# TC37XPD register map
Vendor: Infineon; Series: ATVMC; File version: 100
CPU: other r0p0, little endian, MPU, FPU, vendor SysTick, 4 interrupt priority bits
Registers are 32-bit, read-write, reset 0x0 unless marked. A register's access mark holds for its fields unless they carry their own. Offsets are from the block's base; [hi:lo] are bit positions; lines under a group give offsets from that group; {n}, {i} and the like mark numbered series; 'fields as' and 'values as' point back to an identical list.

## MINIMCDS
Base 0xFB718000
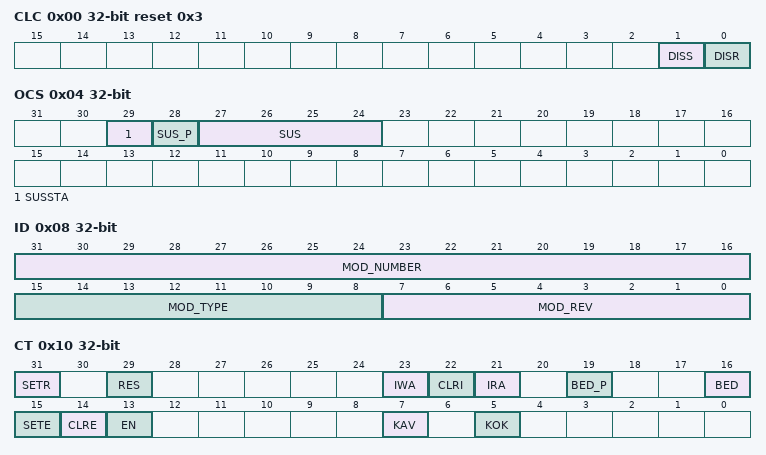
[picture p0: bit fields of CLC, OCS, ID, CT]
0x00 CLC access per field reset 0x3 — Clock Control Register resetvalue={PowerOn Reset:0x3}
  [1] DISS ro — Disable Status Bit DISS. This bit field indicates the current clocking state.
  [0] DISR rw — Disable Request Bit DISR. This bit is used to request a change of the clocking state. Turn off requests are ignored while the Flush flag is not asserted.
0x04 OCS access per field — OCDS Control and Status resetvalue={MCDS Reset:0x0}
  [29] SUSSTA ro — Suspend State inverted busy o SUSSTA
  [28] SUS_P wo — SUS Write Protection SUS P. SUS is only written when SUS P is 1 otherwise unchanged. Read as 0.
  [27:24] SUS rw — OCDS Suspend Control SUS. Controls the sensitivity to the suspend signal coming from the SCU before Power On Reset
0x08 ID ro reset not defined — Module Identification Register resetvalue={PowerOn Reset:0x0D6C007,MCDS Reset:0x0,Debug Reset:0x0}
  [31:16] MOD_NUMBER — Module Number MOD NUMBER
  [15:8] MOD_TYPE — Module Type MOD TYPE
  [7:0] MOD_REV — Module Revision MOD REV. This bit field indicates the revision number of the module implementation.
0x10 CT access per field reset not defined — MCDS Control Register resetvalue={PowerOn Reset:0x0A0,MCDS Reset:0x0,Debug Reset:0x0}
  [31] SETR wo — MCDS ResetRequest Bit SETR. This bit can be used to cause a MCDS Reset affecting debug resources like the MCDS registers as specified in the Reset behavior tables.
  [29] RES ro — MCDS ResetFlag RES. This bit reflects the current value of the MCDS Reset request. Granting of the request will automatically clear this bit.
  [23] IWA ro — Invalid Write Access Flag IWA. This bit field indicates whether any write access to the MCDS address range failed. The MCDS module ignores the data of erroneous writes.
  [22] CLRI wo — Clear Invalid Access Bits CLRI. This control bit is the only way the clear the error bits.
  [21] IRA ro — Invalid Read Access Flag IRA. This bit field indicates whether any read access to the MCDS address range failed. This is not a bus error the MCDS module just returns all zeros in this case.
  [19] BED_P wo — Bus Error Disable Protection BED P. This bit determines whether BED is changed by a write to the CT register.
  [16] BED rw — Bus Error Disable Flag BED. This bit field indicates whether writing to an SFR not implemented in the MCDS address space is considered an error. In TC3xx the usage of this bit is obsolete for miniMCDS.
  [15] SETE wo — Set MCDS Enable Flag SETE. This control bit is the only way to set the MCDS enable flag.
  [14] CLRE wo — Clear MCDS Enable Flag CLRE. This bit allows to reset the MCDS enable Flag by software and thus to write protect the MCDS address range.
  [13] EN ro — MCDS Enable Flag EN. This bit field indicates whether the MCDS is write enabled.
  [7] KAV ro — Key Available Flag KAV. This bit is always set for MINIMCDS .
  [5] KOK ro — Key OK Flag KOK. This bit is always set for MINIMCDS .
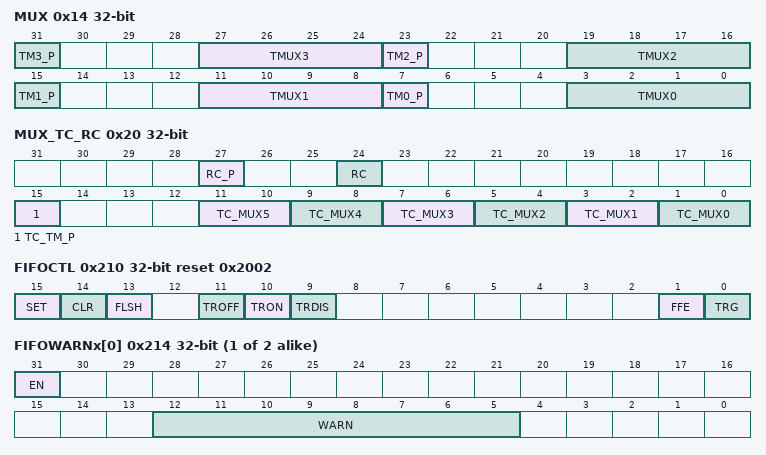
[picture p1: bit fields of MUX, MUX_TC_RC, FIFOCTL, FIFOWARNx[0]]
0x14 MUX access per field — MCDS Signal Source Control resetvalue={PowerOn Reset:0x0}
  [8n+7] TM{n}_P wo (n=0..3) — Trace Source Select 3 Protection TM3 P. This bit determines whether TMUXz is changed by a write to the MUX register. TM1 P TM2 P TM3 P are not relevant for miniMCDS.
  [27:24] TMUX3 rw — Trace Source Select 3 TMUX3. Not relevant for miniMCDS.
  [19:16] TMUX2 rw — Trace Source Select 2 TMUX2. Not relevant for miniMCDS.
  [11:8] TMUX1 rw — Trace Source Select 1 TMUX1. Not relevant for miniMCDS.
  [3:0] TMUX0 rw — Trace Source Select 0 TMUX0. This bit field determines which trace source is seen by POBx. This bit field can only be changed if TM0 P is written x2018 1 x2019 xa0 simultaneously. Not all sources are available in all products of the family. Please refer to Platform Feature Overview table of the TC3xx documentation.
0x20 MUX_TC_RC access per field — MCDS TC Signal Source Control resetvalue={PowerOn Reset:0x0}
  [27] RC_P wo — Reference Clock Select Protection RC P. This bit determines whether RC is changed by a write to the MUX TC RC register.
  [24] RC rw — Reference Clock Select RC. This control bit determines which source is used as reference clock by the TSU. This bit can only be changed if RC P is written 8216 1 8217 160 simultaneously. The reference clock source is sampled with the emulation clock. Therefore no reference clock faster than half the emulation clock must be used.
  [15] TC_TM_P wo — TC MUX Trace Source Select Protection TC TM P. This bit determines whether TC MUXz is changed by a write to the MUX TC RC register.
  [2n+1:2n] TC_MUX{n} rw (n=0..5) — TC MUX Trace Source Select TC MUX5. This bit field determines which trace source is selected. This bit field can only be changed if TC TM P is written 8216 1 8217 160 simultaneously. Not all CPUs are available in all products of the family.
0x200 FIFONOW ro — Trace Buffer Write Pointer resetvalue={PowerOn Reset:0x0}
  [12:5] NOW — Trace Buffer Current Write Pointer NOW. This number is the current value of the DMC s internal write pointer. When tracing stops this register points to the buffer memory word containing the lt end of trace gt message. The relevant width of the field depends on the size of the buffer memory see CROSSREFERENCE
0x204 FIFOBOT — Trace Buffer Bottom Register resetvalue={MCDS Reset:0x0}
  [12:10] BOTTOM — Trace Buffer lower Bound BOTTOM. See CROSSREFERENCE for a functional description. The relevant width of the field depends on the size of the buffer memory see CROSSREFERENCE
0x208 FIFOPRE — Trace Buffer PRE POST Register resetvalue={MCDS Reset:0x0}
  [12:5] PRE — Trace Buffer Pre Trigger Area Size PRE. See CROSSREFERENCE for a functional description. The relevant width of the field depends on the size of the buffer memory see CROSSREFERENCE
0x20C FIFOTOP reset 0x1FFF — Trace Buffer Top Register resetvalue={MCDS Reset:0x1FFF}
  [12:5] TOP — Trace Buffer upper Bound TOP. See CROSSREFERENCE for a functional description. The relevant width of the field depends on the size of the buffer memory see CROSSREFERENCE
0x210 FIFOCTL access per field reset 0x2002 — Trace Buffer Control Register resetvalue={PowerOn Reset:0x2002}
  [15] SET wo — SetFlushFlag SET. This write only bit is the only way to set the Flush flag by software.
  [14] CLR wo — ClearFlushFlag CLR. This write only bit is the only way to start trace recording.
  [13] FLSH ro — FlushFlag FLSH. This bit shows the current state of the Flush control signal. The Flush signal can be set by the SET bit and by the hardware at end of trace . The Flush signal can only be cleared by the CLR bit. This bit is automatically set by MCDS Reset .
  [11] TROFF wo — SetTrigger DisableFlag TROFF. This write only bit is the only way to set the Trigger Disable flag. It is used to mask disable all trigger pools of all TQUs.
  [10] TRON wo — ClearTrigger DisableFlag TRON. This write only bit is used by the tool to globally enable all trigger pools of all TQUs.
  [9] TRDIS ro — Trigger DisableFlag TRDIS. This bit shows the current state of the Trigger Disable control signal. The Trigger Disable signal can be set by the TROFF bit. The Trigger Disable signal can be cleared by the TRON bit. This bit is automatically reset by MCDS Reset .
  [1] FFE ro — FIFO Feeder Empty FFE. This bit indicates that all primary secondary and DMC internal FIFOs have been emptied. After Power On Reset and MCDS Reset this bit will be set automatically as the FIFOs are flushed synchronously.
  [0] TRG ro — Trigger Received Flag TRG. This bit indicated whether the trace recording is in the PRE or POST Trigger area. The switch is controlled by the trace done action of TQU MCX. The TRG flag is cleared by the next CLR bit.
{0x214+4i} FIFOWARNx[{i}] (i=0..1) — Trace Buffer Comparator Register resetvalue={MCDS Reset:0x0}
  [31] EN — Enable Trigger Generation EN
  [12:5] WARN — Trace Buffer Warn Level WARN. See CROSSREFERENCE for a functional description. The relevant width of the field depends on the size of the buffer memory see CROSSREFERENCE
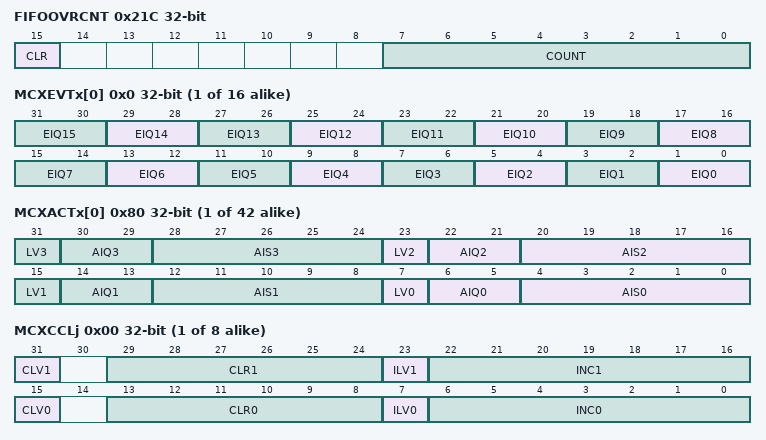
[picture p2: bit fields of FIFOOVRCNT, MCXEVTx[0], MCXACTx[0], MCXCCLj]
0x21C FIFOOVRCNT access per field — FIFO Overflow Counter Register resetvalue={PowerOn Reset:0x0}
  [15] CLR wo — Clear counter CLR
  [7:0] COUNT ro — FIFO Overflow Counter COUNT. The counter increments in case an ERR message is written to one of the Trace Unit FIFOs. In case multiple error messages are written the counter still increments just by one.
0x400 TSUREFCNT ro — Clock Counter Register resetvalue={PowerOn Reset:0x0}
  [31:0] COUNT — Current Count Value COUNT. For a functional description of the counter see CROSSREFERENCE .
0x404 TSUPRSCL — Clock Prescaler Register resetvalue={PowerOn Reset:0x0}
  [31:0] RELOAD — Prescaler Reload Value RELOAD. For a functional description of the prescaler see CROSSREFERENCE .
0x408 TSUEMUCNT ro — Clock Counter Register resetvalue={PowerOn Reset:0x0}
  fields as TSUREFCNT
0x800 MCX group
  {0x0+4j} MCXEVTx[{j}] (j=0..15) — Event Definition Register 0 resetvalue={MCDS Reset:0x0}
    [2n+1:2n] EIQ{n} (n=0..15) — Event Input Qualifier EIQ15. The value in this field determines how the trigger input named in the row of CROSSREFERENCE with value x in the column corresponding to this event definition is connected to the AND gate.
  {0x80+4j} MCXACTx[{j}] (j=0..41) — Action Definition Register 0 resetvalue={MCDS Reset:0x0}
    [8n+7] LV{n} (n=0..3) — Action Input Level Mode LV3. This bit determines how the event selected by AISq and processed according to AIQq is evaluated. The action is active for one emulation clock cycle if LVq is programmed 0.
    [8n+6:8n+5] AIQ{n} (n=0..3) — Action Input Qualifier AIQ3. The value in this field determines how the input bit x is connected to the OR gate edge detection.
    [8n+4:8n] AIS{n} (n=0..3) — Action Input Selector AIS3. Index of the event to be processed. Encoding see CROSSREFERENCE .
  {0x200+0x10*j} CNT[{j}] (j=0..7) group
    0x00 MCXCCLj — Counter Control Register resetvalue={MCDS Reset:0x0}
      [31] CLV1 — Clear Input Level Mode CLV1. For a functional description of the counter see CROSSREFERENCE .
      [29:24] CLR1 — Clear Input Selector CLR1. Index of the event to be processed. Encoding see CROSSREFERENCE . Note that the value 0 in this field does select nothing.
      [23] ILV1 — Count Input Level Mode ILV1. For a functional description of the counter see CROSSREFERENCE .
      [22:16] INC1 — Count Input Selector INC1. Index of the event to be processed. Encoding see CROSSREFERENCE . Note that the value 0 in this field does select nothing.
      [15] CLV0 — Clear Input Level Mode CLV1. For a functional description of the counter see CROSSREFERENCE .
      [13:8] CLR0 — Clear Input Selector CLR1. Index of the event to be processed. Encoding see CROSSREFERENCE . Note that the value 0 in this field does select nothing.
      [7] ILV0 — Count Input Level Mode ILV1. For a functional description of the counter see CROSSREFERENCE .
      [6:0] INC0 — Count Input Selector INC1. Index of the event to be processed. Encoding see CROSSREFERENCE . Note that the value 0 in this field does select nothing.
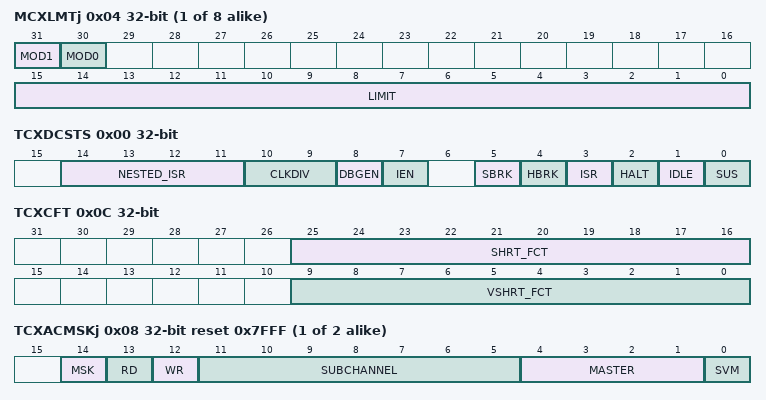
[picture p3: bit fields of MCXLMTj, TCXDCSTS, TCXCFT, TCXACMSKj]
    0x04 MCXLMTj — Counter Limit Register resetvalue={MCDS Reset:0x0}
      [31] MOD1 — Modulo Count Control MOD1. For a functional description of the counter see CROSSREFERENCE .
      [30] MOD0 — Modulo Count Control MOD1. For a functional description of the counter see CROSSREFERENCE .
      [15:0] LIMIT — Counter Limit LIMIT. For a functional description of the counter see CROSSREFERENCE .
    0x08 MCXCNTj ro — Current Count Register resetvalue={PowerOn Reset:0x0}
      [15:0] COUNT — Current Counter COUNT. For a functional description of the counter see CROSSREFERENCE .
0x2000 TCX group
  0x00 TCXDCSTS ro — Debug Status Register resetvalue={PowerOn Reset:0x0}
    [14:11] NESTED_ISR — Nested Interrupt Level NESTED ISR. The nested interrupt level is exactly indicated for nesting levels 0 15. For nesting levels greater 15 the value shown is 0xF.
    [10:9] CLKDIV — Current Clock Divider CLKDIV. The SCU provides the clock for the TriCore as well as for MCDS. The current ration is reported here.
    [8] DBGEN — Debug Enabled Flag DBGEN
    [7] IEN — Interrupt Enable Flag IEN
    [5] SBRK — Software Break Flag SBRK. This bit reflects the reaction to a DEBUG instruction filtered by the SWEVT register.
    [4] HBRK — Hardware Break Flag HBRK. This bit reflects the reaction to a break request from a OTGS trigger line filtered by the EXEVT register.
    [3] ISR — Interrupt Service Flag ISR. This bit indicated whether regular code or a trap interrupt handler is executed.
    [2] HALT — Halted Flag HALT. This is basically the DBGSR.HALT bit.
    [1] IDLE — Run Flag IDLE
    [0] SUS — Suspended Flag SUS
  0x08 TCXCIP ro — Current Instruction Pointer resetvalue={PowerOn Reset:0x0}
    [31:1] CURRENT — Current Instruction Pointer CURRENT. To help debugging the last valid value is kept when the TriCore stops executing. The value 0000 0000 indicates that no valid IP was ever seen.
  0x0C TCXCFT — Compact Function Trace Register resetvalue={MCDS Reset:0x0}
    [25:16] SHRT_FCT — Length of short leaf function SHRT FCT. This value has to be greater than VSHRT FCT if VSHRT FCT lt gt 0.
    [9:0] VSHRT_FCT — Length of very short leaf function VSHRT FCT. A TriCore 16 bit instruction corresponds to a value of 1 a 32 bit instruction to a value of 2.
  {0x400+0x10*j} EA[{j}] (j=0..1) group
    0x00 TCXEABNDj — Comparator Bound Register 0 resetvalue={MCDS Reset:0x0}
      [31:0] BOUND — Address Comparator range lower bound BOUND. For a functional description of the comparator see CROSSREFERENCE . When defining the comparators for the effective address keep in mind that many memory locations can be accessed under two different addresses namely as cached or non cached memory range.
    0x04 TCXEARNGj reset 0xFFFFFFFF — Comparator Range Register 0 resetvalue={MCDS Reset:0x0FFFFFFFF}
      [31:0] RANGE — Address Comparator range size RANGE. For a functional description of the comparator see CROSSREFERENCE .
  {0x480+0x20*j} WD[{j}] (j=0..1) group
    0x00 TCXWDBNDj — Comparator Bound Register 0 resetvalue={MCDS Reset:0x0}
      [31:0] BOUND — Data Comparator range lower bound BOUND. For a functional description of the comparator see CROSSREFERENCE .
    0x08 TCXWDRNGj — Comparator Range Register 0 resetvalue={MCDS Reset:0x0}
      [31:0] RANGE — Data Comparator range size RANGE. For a functional description of the comparator see CROSSREFERENCE .
    0x10 TCXWDMSKj reset 0xFFFFFFFF — Comparator Mask Register 0 resetvalue={MCDS Reset:0x0FFFFFFFF}
      [31:0] MASK — Data Comparator bit mask MASK. For a functional description of the comparator see CROSSREFERENCE .
    0x1C TCXWDSGNj — Comparator Sign Register 0 resetvalue={MCDS Reset:0x0}
      [4:0] SIGN — Bit number 1 31 of sign bit SIGN. For a functional description of the comparator see CROSSREFERENCE .
  {0x500+0x18*j} AC[{j}] (j=0..1) group
    0x00 TCXACBNDj — Comparator Bound Register 0 resetvalue={MCDS Reset:0x0}
      [13:0] BOUND — Mode Comparator range lower bound BOUND. The bit string consisting of SVM bus master ID sub channel and direction masked by TCXACMSKx is compared to this lower bound. For a functional description of the comparator see CROSSREFERENCE .
    0x04 TCXACRNGj — Comparator Range Register 0 resetvalue={MCDS Reset:0x0}
      [13:0] RANGE — Mode Comparator range size RANGE. For a functional description of the comparator see CROSSREFERENCE .
    0x08 TCXACMSKj reset 0x7FFF — Comparator Mask Register 0 resetvalue={MCDS Reset:0x7FFF}
      [14] MSK — Bit mask for Transaction Type MSK. For a functional description of the comparator see CROSSREFERENCE . The MSK bits of a register group are ORed. Setting the bit in one of the registers x 0 3 enables the bit mask functionality.
      [13] RD — Comparator bit mask for Direction Read RD. For a functional description of the comparator see CROSSREFERENCE .
      [12] WR — Comparator bit mask for Direction Write WR. For a functional description of the comparator see CROSSREFERENCE .
      [11:5] SUBCHANNEL — Comparator bit mask for Sub channel ID SUBCHANNEL. The sub channel ID from the bus encoding see CROSSREFERENCE is ANDed with this bit pattern and the result used as bit 11 5 for the comparison. For a functional description of the comparator see CROSSREFERENCE .
      [4:1] MASTER — Comparator bit mask for Master ID MASTER. The master ID from the bus encoding see CROSSREFERENCE is ANDed with this bit pattern and the result used as bit 4 1 for the comparison. For a functional description of the comparator see CROSSREFERENCE .
      [0] SVM — Comparator bit mask for Supervisor Mode SVM. For a functional description of the comparator see CROSSREFERENCE .
  {0x1000+0x10*j} IP[{j}] (j=0..1) group
    0x00 TCXIPBNDj — Comparator Bound Register 0 resetvalue={MCDS Reset:0x0}
      [31:1] BOUND — IP Comparator range lower bound BOUND. As TriCore instructions are sized in multiples of 16 bit the LSB is fixed to 0. For a functional description of the comparator see CROSSREFERENCE . When defining the comparators for the TriCore instruction pointer keep in mind that many memory locations can be accessed under two different addresses namely as cached or non cached memory range.
    0x04 TCXIPRNGj reset 0xFFFFFFFE — Comparator Range Register 0 resetvalue={MCDS Reset:0x0FFFFFFFE}
      [31:1] RANGE — IP Comparator range size RANGE. As TriCore instructions are sized in multiples of 16 bit the LSB is fixed to 0. For a functional description of the comparator see CROSSREFERENCE .
